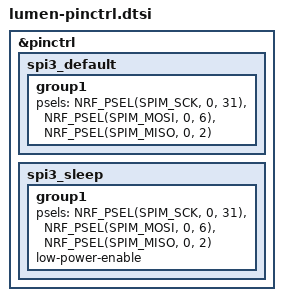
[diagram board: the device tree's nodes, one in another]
/*
 * Copyright (c) 2022 Nordic Semiconductor ASA
 * Copyright (c) 2023 Leon Rinkel
 * SPDX-License-Identifier: Apache-2.0
 */

&pinctrl {
	spi3_default: spi3_default {
		group1 {
			psels = <NRF_PSEL(SPIM_SCK, 0, 31)>,
				<NRF_PSEL(SPIM_MOSI, 0, 6)>,
				<NRF_PSEL(SPIM_MISO, 0, 2)>;
		};
	};
	spi3_sleep: spi3_sleep {
		group1 {
			psels = <NRF_PSEL(SPIM_SCK, 0, 31)>,
				<NRF_PSEL(SPIM_MOSI, 0, 6)>,
				<NRF_PSEL(SPIM_MISO, 0, 2)>;
			low-power-enable;
		};
	};
};
